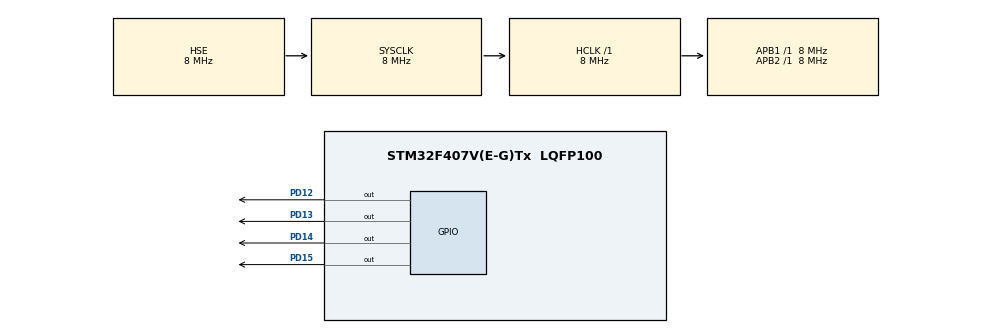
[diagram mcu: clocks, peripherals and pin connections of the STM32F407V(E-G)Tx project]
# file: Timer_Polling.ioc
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Mcu.Family=STM32F4
Mcu.Name=STM32F407V(E-G)Tx
Mcu.Package=LQFP100
NVIC.PriorityGroup=NVIC_PRIORITYGROUP_4
PA13.Mode=Serial_Wire
PA13.Signal=SYS_JTMS-SWDIO
PA14.Mode=Serial_Wire
PA14.Signal=SYS_JTCK-SWCLK
PD12.Signal=GPIO_Output
PD13.Signal=GPIO_Output
PD14.Signal=GPIO_Output
PD15.Signal=GPIO_Output
PH0-OSC_IN.Mode=HSE-External-Oscillator
PH0-OSC_IN.Signal=RCC_OSC_IN
PH1-OSC_OUT.Mode=HSE-External-Oscillator
PH1-OSC_OUT.Signal=RCC_OSC_OUT
ProjectManager.HeapSize=0x200
ProjectManager.StackSize=0x400
ProjectManager.TargetToolchain=MDK-ARM V5.32
RCC.AHBFreq_Value=8000000
RCC.APB1Freq_Value=8000000
RCC.APB1TimFreq_Value=8000000
RCC.APB2Freq_Value=8000000
RCC.APB2TimFreq_Value=8000000
RCC.CortexFreq_Value=8000000
RCC.EnbaleCSS=true
RCC.HCLKFreq_Value=8000000
RCC.HSE_VALUE=8000000
RCC.HSI_VALUE=16000000
RCC.LSE_VALUE=32768
RCC.SYSCLKFreq_VALUE=8000000
RCC.SYSCLKSource=RCC_SYSCLKSOURCE_HSE
RCC.VCOOutputFreq_Value=192000000
TIM7.AutoReloadPreload=TIM_AUTORELOAD_PRELOAD_ENABLE
TIM7.Period=999
TIM7.Prescaler=7999
VP_TIM7_VS_ClockSourceINT.Mode=Enable_Timer
board=custom

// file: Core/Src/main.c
/* USER CODE BEGIN Header */
/**
  ******************************************************************************
  * @file           : main.c
  * @brief          : Main program body
  ******************************************************************************
  * @attention
  *
  * Copyright (c) 2026 STMicroelectronics.
  * All rights reserved.
  *
  * This software is licensed under terms that can be found in the LICENSE file
  * in the root directory of this software component.
  * If no LICENSE file comes with this software, it is provided AS-IS.
  *
  ******************************************************************************
  */
/* USER CODE END Header */
#include "main.h"

TIM_HandleTypeDef htim7;

void SystemClock_Config(void);
static void MX_GPIO_Init(void);
static void MX_TIM7_Init(void);

int main(void)
{

  /* MCU Configuration--------------------------------------------------------*/

  /* Reset of all peripherals, Initializes the Flash interface and the Systick. */
  HAL_Init();

  /* Configure the system clock */
  SystemClock_Config();

  /* Initialize all configured peripherals */
  MX_GPIO_Init();
  MX_TIM7_Init();
  /* USER CODE BEGIN 2 */
	TIM_TypeDef* TIM_TypeDef_Ptr1;

	TIM_TypeDef_Ptr1 = htim7.Instance;
	HAL_TIM_Base_Start(&htim7);
  /* USER CODE END 2 */

  /* Infinite loop */
  while (1)
  {
    /* USER CODE BEGIN 3 */
		if((TIM_TypeDef_Ptr1->SR & TIM_FLAG_UPDATE) != 0)
		{
			HAL_GPIO_TogglePin(GPIOD, GPIO_PIN_12);
			HAL_GPIO_TogglePin(GPIOD, GPIO_PIN_13);
			HAL_GPIO_TogglePin(GPIOD, GPIO_PIN_14);
			HAL_GPIO_TogglePin(GPIOD, GPIO_PIN_15);

			__HAL_TIM_CLEAR_FLAG(&htim7, TIM_FLAG_UPDATE);
		}
  }
  /* USER CODE END 3 */
}

void SystemClock_Config(void)
{
  RCC_OscInitTypeDef RCC_OscInitStruct = {0};
  RCC_ClkInitTypeDef RCC_ClkInitStruct = {0};

  /** Configure the main internal regulator output voltage
  */
  __HAL_RCC_PWR_CLK_ENABLE();
  __HAL_PWR_VOLTAGESCALING_CONFIG(PWR_REGULATOR_VOLTAGE_SCALE1);

  /** Initializes the RCC Oscillators according to the specified parameters
  * in the RCC_OscInitTypeDef structure.
  */
  RCC_OscInitStruct.OscillatorType = RCC_OSCILLATORTYPE_HSE;
  RCC_OscInitStruct.HSEState = RCC_HSE_ON;
  RCC_OscInitStruct.PLL.PLLState = RCC_PLL_NONE;
  if (HAL_RCC_OscConfig(&RCC_OscInitStruct) != HAL_OK)
  {
    Error_Handler();
  }

  /** Initializes the CPU, AHB and APB buses clocks
  */
  RCC_ClkInitStruct.ClockType = RCC_CLOCKTYPE_HCLK|RCC_CLOCKTYPE_SYSCLK
                              |RCC_CLOCKTYPE_PCLK1|RCC_CLOCKTYPE_PCLK2;
  RCC_ClkInitStruct.SYSCLKSource = RCC_SYSCLKSOURCE_HSE;
  RCC_ClkInitStruct.AHBCLKDivider = RCC_SYSCLK_DIV1;
  RCC_ClkInitStruct.APB1CLKDivider = RCC_HCLK_DIV1;
  RCC_ClkInitStruct.APB2CLKDivider = RCC_HCLK_DIV1;

  if (HAL_RCC_ClockConfig(&RCC_ClkInitStruct, FLASH_LATENCY_0) != HAL_OK)
  {
    Error_Handler();
  }

  /** Enables the Clock Security System
  */
  HAL_RCC_EnableCSS();
}

static void MX_TIM7_Init(void)
{

  TIM_MasterConfigTypeDef sMasterConfig = {0};

  htim7.Instance = TIM7;
  htim7.Init.Prescaler = 7999;
  htim7.Init.CounterMode = TIM_COUNTERMODE_UP;
  htim7.Init.Period = 999;
  htim7.Init.AutoReloadPreload = TIM_AUTORELOAD_PRELOAD_ENABLE;
  if (HAL_TIM_Base_Init(&htim7) != HAL_OK)
  {
    Error_Handler();
  }
  sMasterConfig.MasterOutputTrigger = TIM_TRGO_RESET;
  sMasterConfig.MasterSlaveMode = TIM_MASTERSLAVEMODE_DISABLE;
  if (HAL_TIMEx_MasterConfigSynchronization(&htim7, &sMasterConfig) != HAL_OK)
  {
    Error_Handler();
  }

}

static void MX_GPIO_Init(void)
{
  GPIO_InitTypeDef GPIO_InitStruct = {0};

  /* GPIO Ports Clock Enable */
  __HAL_RCC_GPIOH_CLK_ENABLE();
  __HAL_RCC_GPIOD_CLK_ENABLE();
  __HAL_RCC_GPIOA_CLK_ENABLE();

  /*Configure GPIO pin Output Level */
  HAL_GPIO_WritePin(GPIOD, GPIO_PIN_12|GPIO_PIN_13|GPIO_PIN_14|GPIO_PIN_15, GPIO_PIN_RESET);

  /*Configure GPIO pins : PD12 PD13 PD14 PD15 */
  GPIO_InitStruct.Pin = GPIO_PIN_12|GPIO_PIN_13|GPIO_PIN_14|GPIO_PIN_15;
  GPIO_InitStruct.Mode = GPIO_MODE_OUTPUT_PP;
  GPIO_InitStruct.Pull = GPIO_NOPULL;
  GPIO_InitStruct.Speed = GPIO_SPEED_FREQ_LOW;
  HAL_GPIO_Init(GPIOD, &GPIO_InitStruct);

}

void Error_Handler(void)
{
  __disable_irq();
  while (1)
  {
  }
}
